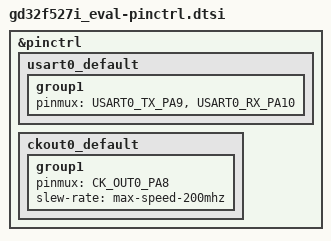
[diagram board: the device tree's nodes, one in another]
/*
 * Copyright (c) 2026 GigaDevice Semiconductor Inc.
 *
 * SPDX-License-Identifier: Apache-2.0
 */

#include <dt-bindings/pinctrl/gd32f527i(m-s)xx-pinctrl.h>

&pinctrl {
	usart0_default: usart0_default {
		group1 {
			pinmux = <USART0_TX_PA9>, <USART0_RX_PA10>;
		};
	};

	ckout0_default: ckout0_default {
		group1 {
			pinmux = <CK_OUT0_PA8>;
			slew-rate = "max-speed-200mhz";
		};
	};
};
